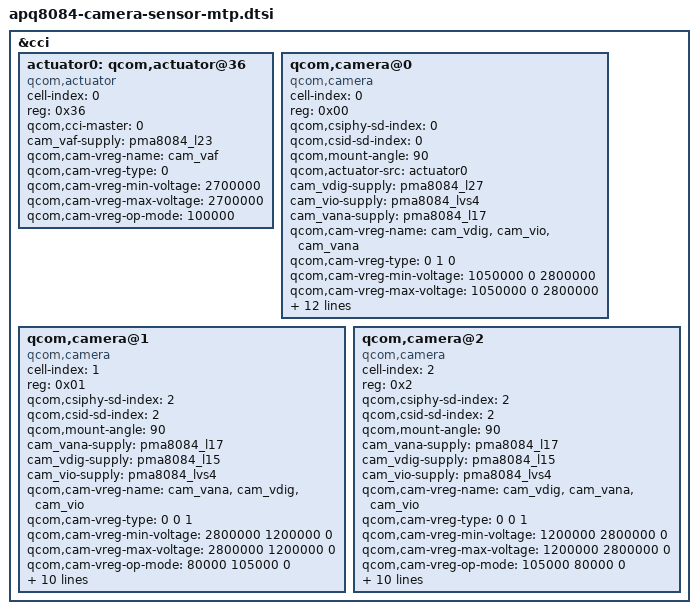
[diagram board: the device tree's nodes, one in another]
/*
 * Copyright (c) 2013 - 2014, The Linux Foundation. All rights reserved.
 *
 * This program is free software; you can redistribute it and/or modify
 * it under the terms of the GNU General Public License version 2 and
 * only version 2 as published by the Free Software Foundation.
 *
 * This program is distributed in the hope that it will be useful,
 * but WITHOUT ANY WARRANTY; without even the implied warranty of
 * MERCHANTABILITY or FITNESS FOR A PARTICULAR PURPOSE.  See the
 * GNU General Public License for more details.
 */

&cci {
	actuator0: qcom,actuator@36 {
		cell-index = <0>;
		reg = <0x36>;
		compatible = "qcom,actuator";
		qcom,cci-master = <0>;
		cam_vaf-supply = <&pma8084_l23>;
		qcom,cam-vreg-name = "cam_vaf";
		qcom,cam-vreg-type = <0>;
		qcom,cam-vreg-min-voltage = <2700000>;
		qcom,cam-vreg-max-voltage = <2700000>;
		qcom,cam-vreg-op-mode = <100000>;
	};

	qcom,camera@0 {
		cell-index = <0>;
		compatible = "qcom,camera";
		reg = <0x00>;
		qcom,csiphy-sd-index = <0>;
		qcom,csid-sd-index = <0>;
		qcom,mount-angle = <90>;
                qcom,actuator-src = <&actuator0>;
		cam_vdig-supply = <&pma8084_l27>;
		cam_vio-supply = <&pma8084_lvs4>;
		cam_vana-supply = <&pma8084_l17>;
		qcom,cam-vreg-name = "cam_vdig", "cam_vio", "cam_vana";
		qcom,cam-vreg-type = <0 1 0>;
		qcom,cam-vreg-min-voltage = <1050000 0 2800000>;
		qcom,cam-vreg-max-voltage = <1050000 0 2800000>;
		qcom,cam-vreg-op-mode = <105000 0 80000>;
		qcom,gpio-no-mux = <0>;
		gpios = <&msmgpio 15 0>,
			<&msmgpio 36 0>,
			<&msmgpio 35 0>;
		qcom,gpio-reset = <1>;
		qcom,gpio-standby = <2>;
		qcom,gpio-req-tbl-num = <0 1 2>;
		qcom,gpio-req-tbl-flags = <1 0 0>;
		qcom,gpio-req-tbl-label = "CAMIF_MCLK",
					  "CAM_RESET1",
					  "CAM_STANDBY";
		qcom,sensor-position = <0>;
		qcom,sensor-mode = <1>;
		qcom,cci-master = <0>;
		status = "ok";
	};

	qcom,camera@1 {
		cell-index = <1>;
		compatible = "qcom,camera";
		reg = <0x01>;
		qcom,csiphy-sd-index = <2>;
		qcom,csid-sd-index = <2>;
		qcom,mount-angle = <90>;
		cam_vana-supply = <&pma8084_l17>;
		cam_vdig-supply = <&pma8084_l15>;
		cam_vio-supply = <&pma8084_lvs4>;
		qcom,cam-vreg-name =  "cam_vana", "cam_vdig", "cam_vio";
		qcom,cam-vreg-type = <0 0 1>;
		qcom,cam-vreg-min-voltage = <2800000 1200000 0>;
		qcom,cam-vreg-max-voltage = <2800000 1200000 0>;
		qcom,cam-vreg-op-mode = <80000 105000 0>;
		qcom,gpio-no-mux = <0>;
		gpios = <&msmgpio 17 0>,
			    <&msmgpio 25 0>;
		qcom,gpio-reset = <1>;
		qcom,gpio-req-tbl-num = <0 1>;
		qcom,gpio-req-tbl-flags = <1 0>;
		qcom,gpio-req-tbl-label = "CAMIF_MCLK2",
					  "CAM_XSHUTDOWN";
		qcom,sensor-position = <1>;
		qcom,sensor-mode = <1>;
		qcom,cci-master = <0>;
		status = "ok";
	};

	qcom,camera@2 {
		cell-index = <2>;
		compatible = "qcom,camera";
		reg = <0x2>;
		qcom,csiphy-sd-index = <2>;
		qcom,csid-sd-index = <2>;
		qcom,mount-angle = <90>;
		cam_vana-supply = <&pma8084_l17>;
		cam_vdig-supply = <&pma8084_l15>;
		cam_vio-supply = <&pma8084_lvs4>;
		qcom,cam-vreg-name = "cam_vdig", "cam_vana", "cam_vio";
		qcom,cam-vreg-type = <0 0 1>;
		qcom,cam-vreg-min-voltage = <1200000 2800000 0>;
		qcom,cam-vreg-max-voltage = <1200000 2800000 0>;
		qcom,cam-vreg-op-mode = <105000 80000 0>;
		qcom,gpio-no-mux = <0>;
		gpios = <&msmgpio 17 0>,
			<&msmgpio 18 0>,
			<&msmgpio 28 0>;
		qcom,gpio-reset = <1>;
		qcom,gpio-req-tbl-num = <0 1 2>;
		qcom,gpio-req-tbl-flags = <1 0 0>;
		qcom,gpio-req-tbl-label = "CAMIF_MCLK2",
					  "CAM_RESET2",
					  "CAM_STANDBY2";
		qcom,sensor-position = <1>;
		qcom,sensor-mode = <1>;
		qcom,cci-master = <0>;
		status = "ok";
	};
};
